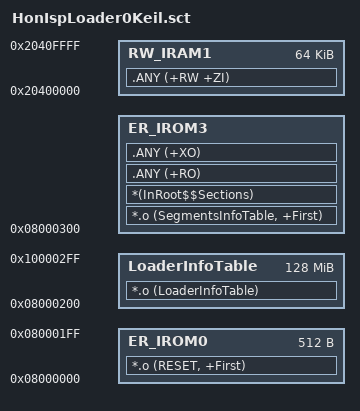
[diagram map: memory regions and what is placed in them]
; *************************************************************
; *** Scatter-Loading Description File generated by uVision ***
; *************************************************************
LR_IROM0 0x08000000 0x200  {    ; load region size_region
  ER_IROM0 0x08000000 0x200  {  ; load address = execution address
   *.o (RESET, +First)
  }
}
LR_IROM1 0x08000200 0x100  {    ; load region size_region
  LoaderInfoTable 0x08000200 0x08000100  {  ; load address = execution address
   *.o (LoaderInfoTable)
  }
}
LR_IROM2 0x08000300 0x00010000  {    ; load region size_region
  ER_IROM3 0x08000300  {  ; load address = execution address
   *.o (SegmentsInfoTable, +First)
   *(InRoot$$Sections)
   .ANY (+RO)
   .ANY (+XO)
  }
  RW_IRAM1 0x20400000 0x00010000  {  ; RW data
   .ANY (+RW +ZI)
  }
}

